# NUC200AE_v1 register map
File version: 1.0
Registers are 32-bit, read-write, reset 0x0 unless marked. A register's access mark holds for its fields unless they carry their own. Offsets are from the block's base; [hi:lo] are bit positions; {n}, {i} and the like mark numbered series.

## RTC — RTC Register Map
Base 0x40008000
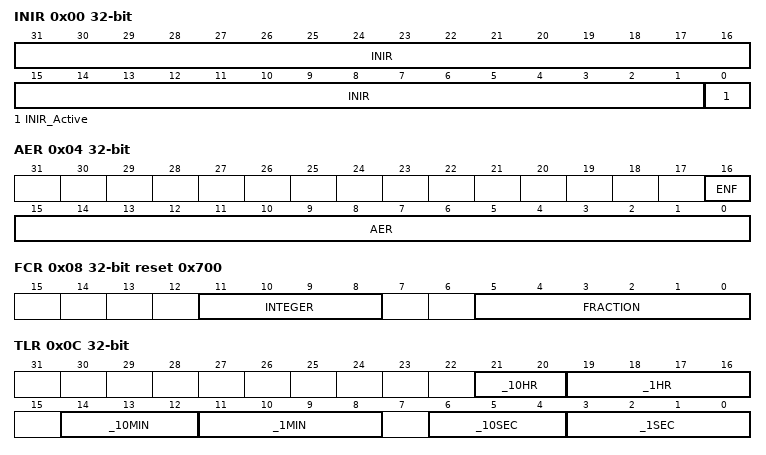
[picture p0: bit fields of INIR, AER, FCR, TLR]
0x00 INIR — RTC Initiation Register
  [31:1] INIR — RTC Initiation. When RTC block is powered on, RTC is at reset state. User has to write a number (0xa5eb1357) to INIR to make RTC leaving reset state. Once the INIR is written as 0xa5eb1357, the RTC will be in un-reset state permanently. The INIR is a write-only field and read value will be always 0.
  [0] INIR_Active ro — RTC Active Status (Read Only)
    0=RTC is at reset state; 1=RTC is at normal active state
0x04 AER — RTC Access Enable Register
  [16] ENF ro — RTC Register Access Enable Flag (Read Only). Note: This bit will be set after AER[15:0] is load a 0xA965, and will be cleared automatically after 1024 RTC clocks.
    0=RTC register read/write access Disabled; 1=RTC register read/write access Enabled
  [15:0] AER wo — RTC Register Access Enable Password (Write Only). Writing 0xA965 to this register will enable RTC access and keep 1024 RTC clocks.
0x08 FCR reset 0x700 — RTC Frequency Compensation Register
  [11:8] INTEGER — Integer Part. Please refer to 5.14.5.4 .
  [5:0] FRACTION — Fraction Part. Note: Digit in FCR must be expressed as hexadecimal number..
0x0C TLR — Time Loading Register
  [21:20] _10HR — 10-Hour Time Digit (0~2)
  [19:16] _1HR — 1-Hour Time Digit (0~9)
  [14:12] _10MIN — 10-Min Time Digit (0~5)
  [11:8] _1MIN — 1-Min Time Digit (0~9)
  [6:4] _10SEC — 10-Sec Time Digit (0~5)
  [3:0] _1SEC — 1-Sec Time Digit (0~9)
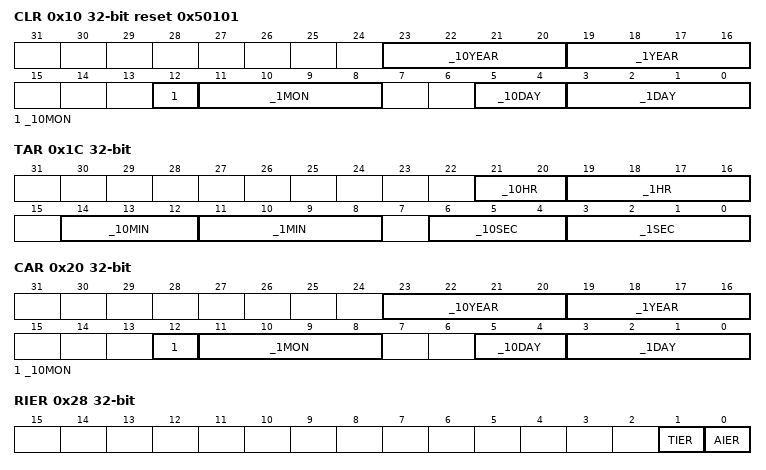
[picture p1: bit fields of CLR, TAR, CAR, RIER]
0x10 CLR reset 0x50101 — Calendar Loading Register
  [23:20] _10YEAR — 10-Year Calendar Digit (0~9)
  [19:16] _1YEAR — 1-Year Calendar Digit (0~9)
  [12] _10MON — 10-Month Calendar Digit (0~1)
  [11:8] _1MON — 1-Month Calendar Digit (0~9)
  [5:4] _10DAY — 10-Day Calendar Digit (0~3)
  [3:0] _1DAY — 1-Day Calendar Digit (0~9)
0x14 TSSR reset 0x1 — Time Scale Selection Register
  [0] _24H_12H — 24-Hour / 12-Hour Time Scale Selection. It indicates that RTC TLR and TAR counter are in 24-hour time scale or 12-hour time scale. Please refer to 5.14.5.6 .
    0=24-hour time scale selected; 1=24-hour time scale selected
0x18 DWR reset 0x6 — Day of the Week Register
  [2:0] DWR — Day Of The Week Register
    0=Sunday; 1=Monday; 2=Tuesday; 3=Wednesday; 4=Thursday; 5=Friday; 6=Saturday
0x1C TAR — Time Alarm Register
  [21:20] _10HR — 10-Hour Time Digit of Alarm Setting (0~2)
  [19:16] _1HR — 1-Hour Time Digit of Alarm Setting (0~9)
  [14:12] _10MIN — 10-Min Time Digit of Alarm Setting (0~5)
  [11:8] _1MIN — 1-Min Time Digit of Alarm Setting (0~9)
  [6:4] _10SEC — 10-Sec Time Digit of Alarm Setting (0~5)
  [3:0] _1SEC — 1-Sec Time Digit of Alarm Setting (0~9)
0x20 CAR — Calendar Alarm Register
  [23:20] _10YEAR — 10-Year Calendar Digit of Alarm Setting (0~9)
  [19:16] _1YEAR — 1-Year Calendar Digit of Alarm Setting (0~9)
  [12] _10MON — 10-Month Calendar Digit of Alarm Setting (0~1)
  [11:8] _1MON — 1-Month Calendar Digit of Alarm Setting (0~9)
  [5:4] _10DAY — 10-Day Calendar Digit of Alarm Setting (0~3)
  [3:0] _1DAY — 1-Day Calendar Digit of Alarm Setting (0~9)
0x24 LIR ro — Leap Year Indicator Register
  [0] LIR — Leap Year Indication Register (Read Only)
    0=This year is not a leap year; 1=This year is a leap year
0x28 RIER — RTC Interrupt Enable Register
  [1] TIER — Time Tick Interrupt Enable Bit. This bit is used to enable/disable RTC Time Tick Interrupt, and generate an interrupt signal if TIF (RIIR[1] RTC Time Tick Interrupt Flag) is set to 1. Note: This bit will also trigger a wake-up event while system runs in Idle/Power-down mode and RTC Time Tick Interrupt signal generated.
    0=RTC Time Tick Interrupt Disabled; 1=RTC Time Tick Interrupt Enabled
  [0] AIER — Alarm Interrupt Enable Bit. This bit is used to enable/disable RTC Alarm Interrupt, and generate an interrupt signal if AIF (RIIR[0] RTC Alarm Interrupt Flag) is set to 1. Note: This bit will also trigger a wake-up event while system runs in Idle/Power-down mode and RTC Alarm Interrupt signal generated.
    0=RTC Alarm Interrupt Disabled; 1=RTC Alarm Interrupt Enabled
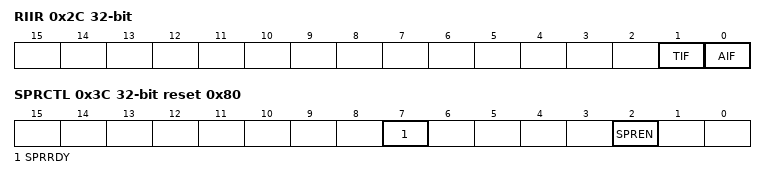
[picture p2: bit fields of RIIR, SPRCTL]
0x2C RIIR — RTC Interrupt Indicator Register
  [1] TIF — RTC Time Tick Interrupt Flag. When RTC time tick happened, this bit will be set to 1 and an interrupt will be generated if RTC Tick Interrupt enabled TIER (RIER[1]) is set to 1. Chip will also be wake-up if RTC Tick Interrupt is enabled and this bit is set to 1 when chip is running at Power-down mode. Note: Write 1 to clear this bit.
    0=Tick condition does not occur; 1=Tick condition occur
  [0] AIF — RTC Alarm Interrupt Flag. When RTC time counters TLR and CLR match the alarm setting time registers TAR and CAR, this bit will be set to 1 and an interrupt will be generated if RTC Alarm Interrupt enabled AIER (RIER[0]) is set to 1. Chip will be wake-up if RTC Alarm Interrupt is enabled when chip is at Power-down mode. Note: Write 1 to clear this bit.
    0=Alarm condition is not matched; 1=Alarm condition is matched
0x30 TTR — RTC Time Tick Register
  [2:0] TTR — Time Tick Register. These bits are used to select RTC time tick period for Periodic Time Tick Interrupt request. Note: This register can be read back after the RTC register access enable bit ENF (AER[16]) is active.
    0=Time tick is 1 second; 1=Time tick is 1/2 second; 2=Time tick is 1/4 second; 3=Time tick is 1/8 second; 4=Time tick is 1/16 second; 5=Time tick is 1/32 second; 6=Time tick is 1/64 second; 7=Time tick is 1/28 second
0x3C SPRCTL reset 0x80 — RTC Spare Functional Control Register
  [7] SPRRDY — SPR Register Ready. This bit indicates if the registers SPRCTL, SPR0 ~ SPR19 are ready to be accessed. After user writing registers SPRCTL, SPR0 ~ SPR19, read this bit to check if these registers are updated done is necessary. Note: This bit is read only and any write to it won't take any effect.
    0=SPRCTL, SPR0 ~ SPR19 updating is in progress; 1=SPRCTL, SPR0 ~ SPR19 are updated done and ready to be accessed
  [2] SPREN — SPR Register Enable Bit. Note: When spare register is disabled, RTC SPR0 ~ SPR19 cannot be accessed.
    0=Spare register is Disabled; 1=Spare register is Enabled
{0x40+4i} SPR{i} (i=0..19) — RTC Spare Register {i}
